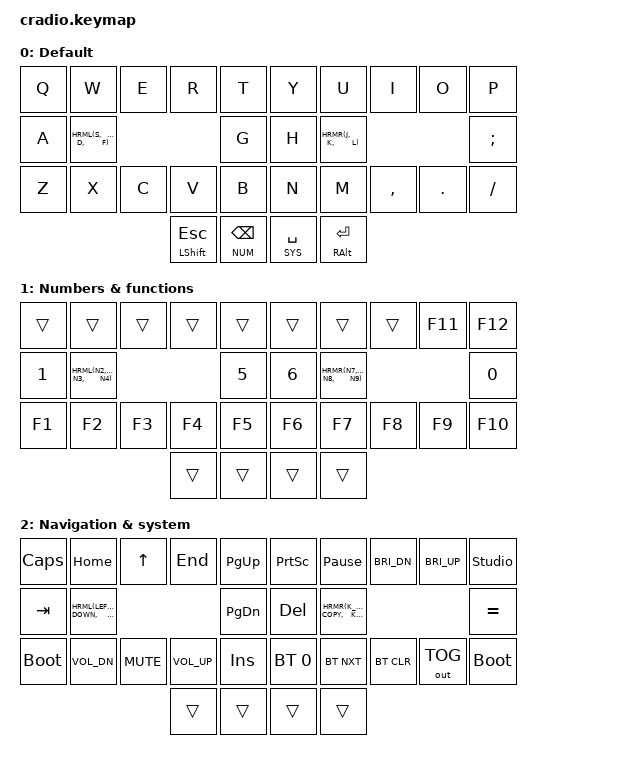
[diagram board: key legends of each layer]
// Copyright (c) 2022 The ZMK Contributors
// SPDX-License-Identifier: MIT

#include <behaviors.dtsi>
#include <dt-bindings/zmk/bt.h>
#include <dt-bindings/zmk/keys.h>
#include <dt-bindings/zmk/outputs.h>

// Home row mods macro
#define HRML(k1,k2,k3) &hml LGUI  k1 &hml LALT k2 &hml LCTRL k3
#define HRMR(k1,k2,k3) &hmr RCTRL k1 &hmr LALT k2 &hml RGUI  k3

// Layer defines https://zmk.dev/docs/keymaps/behaviors/layers#defines-to-refer-to-layers
#define DEFAULT 0
#define NUM 1
#define SYS 2

/ {
    behaviors {
        mt: mod_tap {
            compatible = "zmk,behavior-hold-tap";
            #binding-cells = <2>;
            flavor = "hold-preferred";
            tapping-term-ms = <180>;
            bindings = <&kp>, <&kp>;
            display-name = "Mod-Tap";
        };
	hml: home_row_mod_left {
            compatible = "zmk,behavior-hold-tap";
            #binding-cells = <2>;
            flavor = "balanced";
            require-prior-idle-ms = <100>;
            tapping-term-ms = <200>;
            quick-tap-ms = <150>;
            bindings = <&kp>, <&kp>;
            hold-trigger-key-positions = < 5 6 7 8 9 15 16 17 18 19 25 26 27 28 29 32 33 >; // List of keys on the right side of the keyboard
            hold-trigger-on-release;
        };
        hmr: home_row_mod_right {
            compatible = "zmk,behavior-hold-tap";
            #binding-cells = <2>;
            flavor = "balanced";
            require-prior-idle-ms = <100>;
            tapping-term-ms = <200>;
            quick-tap-ms = <150>;
            bindings = <&kp>, <&kp>;
            hold-trigger-key-positions = < 0 1 2 3 4 10 11 12 13 14 20 21 22 23 24 30 31 >; // List of keys on the left side of the keyboard
            hold-trigger-on-release;
        };
    };

    keymap {
        compatible = "zmk,keymap";
        default_layer {
	    display-name = "Default";
	    bindings = <
        //╭──────────┬──────────┬──────────┬──────────┬──────────╮   ╭──────────┬──────────┬──────────┬──────────┬──────────╮
        //│  Q       │  W       │  E       │  R       │  T       │   │  Y       │  U       │  I       │  O       │  P       │
            &kp Q      &kp W      &kp E      &kp R      &kp T          &kp Y      &kp U      &kp I      &kp O      &kp P
        //├──────────┼──────────┼──────────┼──────────┼──────────┤   ├──────────┼──────────┼──────────┼──────────┼──────────┤
        //│  A       │  S       │  D       │  F       │  G       │   │  H       │  J       │  K       │  L       │  :       │
            &kp A      HRML(S,        D,         F)     &kp G          &kp H      HRMR(J,        K,         L)     &kp SEMI
        //├──────────┼──────────┼──────────┼──────────┼──────────┤   ├──────────┼──────────┼──────────┼──────────┼──────────┤
        //│  Z       │  X       │  C       │  V       │  B       │   │  N       │  M       │ , <      │ . >      │ / ?      │
            &kp Z      &kp X      &kp C      &kp V      &kp B          &kp N      &kp M      &kp COMMA  &kp DOT    &kp FSLH
        //╰──────────┴──────────┴──────────┼──────────┼──────────┤   ├──────────┼──────────┼──────────┴──────────┴──────────╯
                                        &mt LSHIFT ESC &lt NUM BSPC   &lt SYS SPACE &mt RALT RET
        //                                 ╰──────────┴──────────╯   ╰──────────┴──────────╯
            >;
        };

        num_layer {
	    display-name = "Numbers & functions";
            bindings = <
        //╭──────────┬──────────┬──────────┬──────────┬──────────╮   ╭──────────┬──────────┬──────────┬──────────┬──────────╮
        //│          │          │          │          │          │   │          │          │          │  F11     │  F12     │
             &trans     &trans     &trans     &trans     &trans         &trans     &trans     &trans     &kp F11    &kp F12
        //├──────────┼──────────┼──────────┼──────────┼──────────┤   ├──────────┼──────────┼──────────┼──────────┼──────────┤
        //│  1       │  2       │  3       │  4       │  5       │   │  6       │  7       │  8       │  9       │  0       │
            &kp N1     HRML(N2,      N3,        N4)      &kp N5         &kp N6    HRMR(N7,     N8,        N9)       &kp N0
        //├──────────┼──────────┼──────────┼──────────┼──────────┤   ├──────────┼──────────┼──────────┼──────────┼──────────┤
        //│  F1      │  F2      │  F3      │  F4      │  F5      │   │  F6      │  F7      │  F8      │  F9      │  F10     │
            &kp F1     &kp F2     &kp F3     &kp F4     &kp F5         &kp F6     &kp F7     &kp F8     &kp F9     &kp F10
        //╰──────────┴──────────┴──────────┼──────────┼──────────┤   ├──────────┼──────────┼──────────┴──────────┴──────────╯
                                             &trans     &trans         &trans     &trans
        //                                 ╰──────────┴──────────╯   ╰──────────┴──────────╯
            >;
        };
        navsys_layer {
            display-name = "Navigation & system";
            bindings = <
        //╭──────────┬──────────┬──────────┬──────────┬──────────╮   ╭──────────┬──────────┬──────────┬──────────┬──────────╮
        //│ CAPS LCK │  home    │  up      │  end     │ page up  │   │PRINT SCRN│  PAUSE   │ INC BRIG │ DEC BRIG │UNL STUDIO│
            &kp CAPS   &kp HOME    &kp UP     &kp END   &kp PG_UP   &kp PSCRN &kp PAUSE_BREAK &kp C_BRI_DN &kp C_BRI_UP &studio_unlock
        //├──────────┼──────────┼──────────┼──────────┼──────────┤   ├──────────┼──────────┼──────────┼──────────┼──────────┤
        //│    TAB   │  left    │  down    │  right   │ page dn  │   │ DELETE   │   CUT    │  COPY    │  PASTE   │     =    │
            &kp TAB   HRML(LEFT,   DOWN,      RIGHT)    &kp PG_DN      &kp DEL    HRMR(K_CUT, K_COPY,    K_PASTE)  &kp EQUAL
        //├──────────┼──────────┼──────────┼──────────┼──────────┤   ├──────────┼──────────┼──────────┼──────────┼──────────┤
        //│BOOTLOADER│  vol-    │  mute    │  vol+    │  INSERT  │   │BT PROF 0 │ BT next  │ BT clear │ USB tog  │BOOTLOADER|
         &bootloader &kp C_VOL_DN &kp C_MUTE &kp C_VOL_UP &kp INS   &bt BT_SEL 0 &bt BT_NXT &bt BT_CLR &out OUT_TOG &bootloader
        //╰──────────┴──────────┴──────────┼──────────┼──────────┤   ├──────────┼──────────┼──────────┴──────────┴──────────╯
                                             &trans     &trans         &trans     &trans
        //                                 ╰──────────┴──────────╯   ╰──────────┴──────────╯
            >;
        };

    };
};
